VERSION ""

NS_ :

BS_:

BU_:

BO_ 3221225472 VECTOR__INDEPENDENT_SIG_MSG: 0 Vector__XXX
 SG_ TBD : 0|8@1+ (1,0) [0|0] "" Vector__XXX

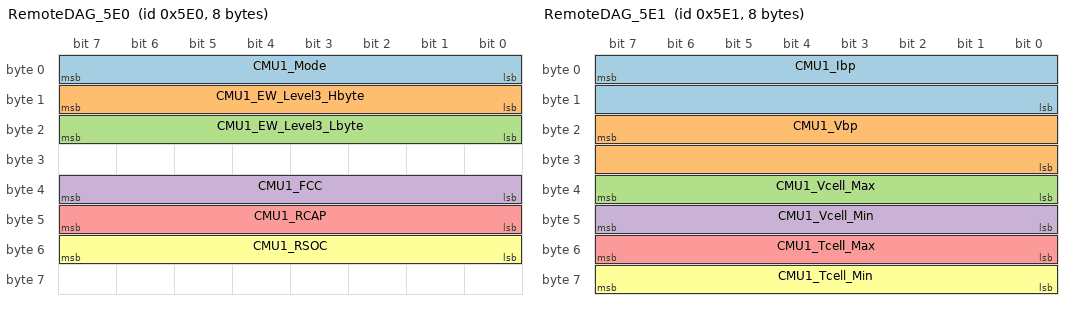
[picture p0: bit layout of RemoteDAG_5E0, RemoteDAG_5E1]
BO_ 1504 RemoteDAG_5E0: 8 Vector__XXX
 SG_ CMU1_Mode : 7|8@0+ (1,0) [0|0] "" Vector__XXX
 SG_ CMU1_EW_Level3_Hbyte : 15|8@0+ (1,0) [0|0] "" Vector__XXX
 SG_ CMU1_EW_Level3_Lbyte : 23|8@0+ (1,0) [0|0] "" Vector__XXX
 SG_ CMU1_FCC : 39|8@0+ (1,0) [0|0] "" Vector__XXX
 SG_ CMU1_RCAP : 47|8@0+ (1,0) [0|0] "" Vector__XXX
 SG_ CMU1_RSOC : 55|8@0+ (1,0) [0|0] "" Vector__XXX

BO_ 1505 RemoteDAG_5E1: 8 Vector__XXX
 SG_ CMU1_Ibp : 7|16@0+ (0.02,-500) [0|0] "" Vector__XXX
 SG_ CMU1_Vbp : 23|16@0+ (0.01,0) [0|0] "" Vector__XXX
 SG_ CMU1_Vcell_Max : 39|8@0+ (1,0) [0|0] "" Vector__XXX
 SG_ CMU1_Vcell_Min : 47|8@0+ (1,0) [0|0] "" Vector__XXX
 SG_ CMU1_Tcell_Max : 55|8@0+ (1,0) [0|0] "" Vector__XXX
 SG_ CMU1_Tcell_Min : 63|8@0+ (1,0) [0|0] "" Vector__XXX

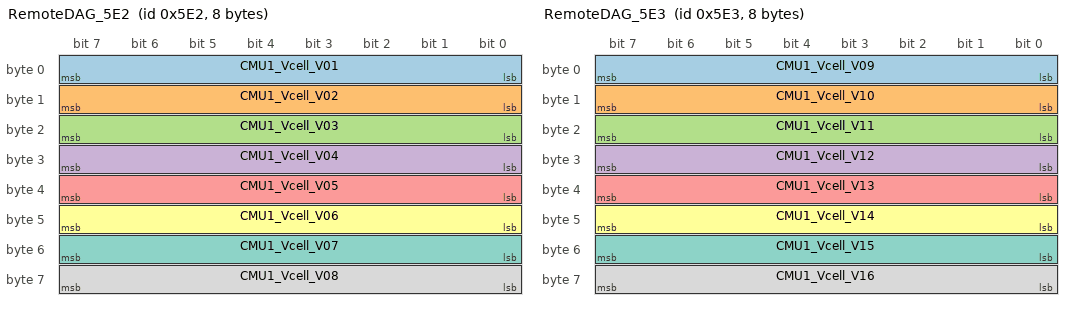
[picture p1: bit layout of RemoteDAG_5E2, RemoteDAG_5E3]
BO_ 1506 RemoteDAG_5E2: 8 Vector__XXX
 SG_ CMU1_Vcell_V01 : 7|8@0+ (1,0) [0|0] "" Vector__XXX
 SG_ CMU1_Vcell_V02 : 15|8@0+ (1,0) [0|0] "" Vector__XXX
 SG_ CMU1_Vcell_V03 : 23|8@0+ (1,0) [0|0] "" Vector__XXX
 SG_ CMU1_Vcell_V04 : 31|8@0+ (1,0) [0|0] "" Vector__XXX
 SG_ CMU1_Vcell_V05 : 39|8@0+ (1,0) [0|0] "" Vector__XXX
 SG_ CMU1_Vcell_V06 : 47|8@0+ (1,0) [0|0] "" Vector__XXX
 SG_ CMU1_Vcell_V07 : 55|8@0+ (1,0) [0|0] "" Vector__XXX
 SG_ CMU1_Vcell_V08 : 63|8@0+ (1,0) [0|0] "" Vector__XXX

BO_ 1507 RemoteDAG_5E3: 8 Vector__XXX
 SG_ CMU1_Vcell_V09 : 7|8@0+ (1,0) [0|0] "" Vector__XXX
 SG_ CMU1_Vcell_V10 : 15|8@0+ (1,0) [0|0] "" Vector__XXX
 SG_ CMU1_Vcell_V11 : 23|8@0+ (1,0) [0|0] "" Vector__XXX
 SG_ CMU1_Vcell_V12 : 31|8@0+ (1,0) [0|0] "" Vector__XXX
 SG_ CMU1_Vcell_V13 : 39|8@0+ (1,0) [0|0] "" Vector__XXX
 SG_ CMU1_Vcell_V14 : 47|8@0+ (1,0) [0|0] "" Vector__XXX
 SG_ CMU1_Vcell_V15 : 55|8@0+ (1,0) [0|0] "" Vector__XXX
 SG_ CMU1_Vcell_V16 : 63|8@0+ (1,0) [0|0] "" Vector__XXX

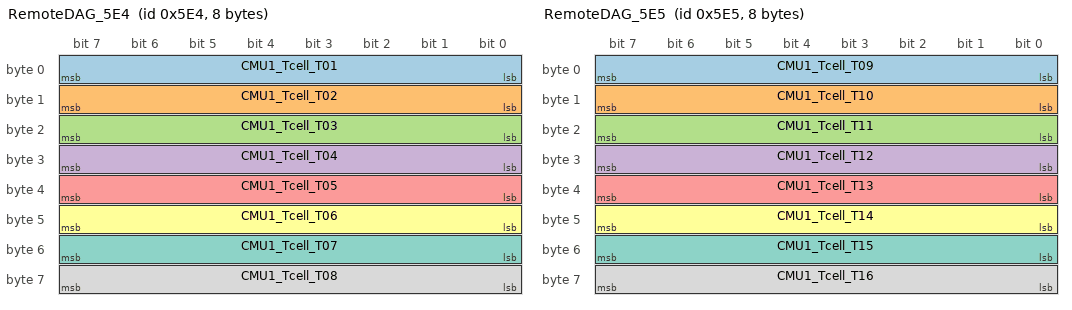
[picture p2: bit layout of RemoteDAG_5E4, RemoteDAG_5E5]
BO_ 1508 RemoteDAG_5E4: 8 Vector__XXX
 SG_ CMU1_Tcell_T01 : 7|8@0+ (1,0) [0|0] "" Vector__XXX
 SG_ CMU1_Tcell_T02 : 15|8@0+ (1,0) [0|0] "" Vector__XXX
 SG_ CMU1_Tcell_T03 : 23|8@0+ (1,0) [0|0] "" Vector__XXX
 SG_ CMU1_Tcell_T04 : 31|8@0+ (1,0) [0|0] "" Vector__XXX
 SG_ CMU1_Tcell_T05 : 39|8@0+ (1,0) [0|0] "" Vector__XXX
 SG_ CMU1_Tcell_T06 : 47|8@0+ (1,0) [0|0] "" Vector__XXX
 SG_ CMU1_Tcell_T07 : 55|8@0+ (1,0) [0|0] "" Vector__XXX
 SG_ CMU1_Tcell_T08 : 63|8@0+ (1,0) [0|0] "" Vector__XXX

BO_ 1509 RemoteDAG_5E5: 8 Vector__XXX
 SG_ CMU1_Tcell_T09 : 7|8@0+ (1,0) [0|0] "" Vector__XXX
 SG_ CMU1_Tcell_T10 : 15|8@0+ (1,0) [0|0] "" Vector__XXX
 SG_ CMU1_Tcell_T11 : 23|8@0+ (1,0) [0|0] "" Vector__XXX
 SG_ CMU1_Tcell_T12 : 31|8@0+ (1,0) [0|0] "" Vector__XXX
 SG_ CMU1_Tcell_T13 : 39|8@0+ (1,0) [0|0] "" Vector__XXX
 SG_ CMU1_Tcell_T14 : 47|8@0+ (1,0) [0|0] "" Vector__XXX
 SG_ CMU1_Tcell_T15 : 55|8@0+ (1,0) [0|0] "" Vector__XXX
 SG_ CMU1_Tcell_T16 : 63|8@0+ (1,0) [0|0] "" Vector__XXX

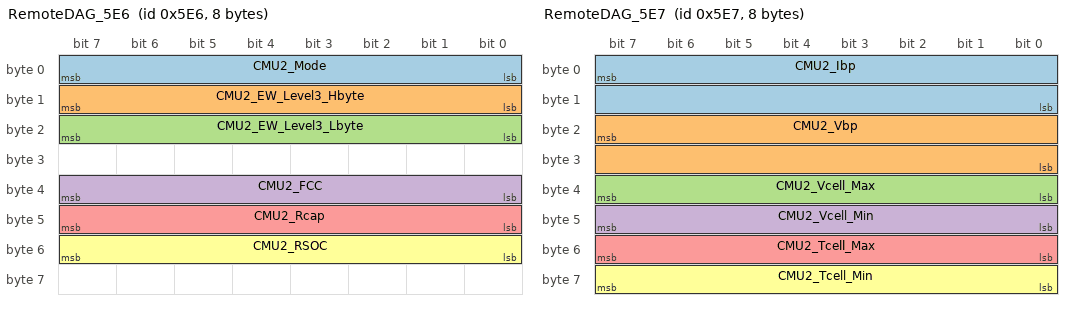
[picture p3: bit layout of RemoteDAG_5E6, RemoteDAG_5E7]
BO_ 1510 RemoteDAG_5E6: 8 Vector__XXX
 SG_ CMU2_Mode : 7|8@0+ (1,0) [0|0] "" Vector__XXX
 SG_ CMU2_EW_Level3_Hbyte : 15|8@0+ (1,0) [0|0] "" Vector__XXX
 SG_ CMU2_EW_Level3_Lbyte : 23|8@0+ (1,0) [0|0] "" Vector__XXX
 SG_ CMU2_FCC : 39|8@0+ (1,0) [0|0] "" Vector__XXX
 SG_ CMU2_Rcap : 47|8@0+ (1,0) [0|0] "" Vector__XXX
 SG_ CMU2_RSOC : 55|8@0+ (1,0) [0|0] "" Vector__XXX

BO_ 1511 RemoteDAG_5E7: 8 Vector__XXX
 SG_ CMU2_Ibp : 7|16@0+ (0.02,-500) [0|0] "" Vector__XXX
 SG_ CMU2_Vbp : 23|16@0+ (0.01,0) [0|0] "" Vector__XXX
 SG_ CMU2_Vcell_Max : 39|8@0+ (1,0) [0|0] "" Vector__XXX
 SG_ CMU2_Vcell_Min : 47|8@0+ (1,0) [0|0] "" Vector__XXX
 SG_ CMU2_Tcell_Max : 55|8@0+ (1,0) [0|0] "" Vector__XXX
 SG_ CMU2_Tcell_Min : 63|8@0+ (1,0) [0|0] "" Vector__XXX

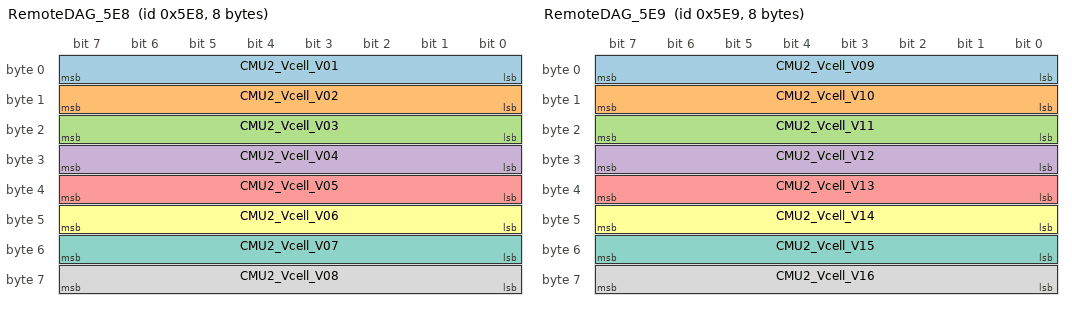
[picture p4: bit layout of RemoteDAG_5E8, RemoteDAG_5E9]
BO_ 1512 RemoteDAG_5E8: 8 Vector__XXX
 SG_ CMU2_Vcell_V01 : 7|8@0+ (1,0) [0|0] "" Vector__XXX
 SG_ CMU2_Vcell_V02 : 15|8@0+ (1,0) [0|0] "" Vector__XXX
 SG_ CMU2_Vcell_V03 : 23|8@0+ (1,0) [0|0] "" Vector__XXX
 SG_ CMU2_Vcell_V04 : 31|8@0+ (1,0) [0|0] "" Vector__XXX
 SG_ CMU2_Vcell_V05 : 39|8@0+ (1,0) [0|0] "" Vector__XXX
 SG_ CMU2_Vcell_V06 : 47|8@0+ (1,0) [0|0] "" Vector__XXX
 SG_ CMU2_Vcell_V07 : 55|8@0+ (1,0) [0|0] "" Vector__XXX
 SG_ CMU2_Vcell_V08 : 63|8@0+ (1,0) [0|0] "" Vector__XXX

BO_ 1513 RemoteDAG_5E9: 8 Vector__XXX
 SG_ CMU2_Vcell_V09 : 7|8@0+ (1,0) [0|0] "" Vector__XXX
 SG_ CMU2_Vcell_V10 : 15|8@0+ (1,0) [0|0] "" Vector__XXX
 SG_ CMU2_Vcell_V11 : 23|8@0+ (1,0) [0|0] "" Vector__XXX
 SG_ CMU2_Vcell_V12 : 31|8@0+ (1,0) [0|0] "" Vector__XXX
 SG_ CMU2_Vcell_V13 : 39|8@0+ (1,0) [0|0] "" Vector__XXX
 SG_ CMU2_Vcell_V14 : 47|8@0+ (1,0) [0|0] "" Vector__XXX
 SG_ CMU2_Vcell_V15 : 55|8@0+ (1,0) [0|0] "" Vector__XXX
 SG_ CMU2_Vcell_V16 : 63|8@0+ (1,0) [0|0] "" Vector__XXX

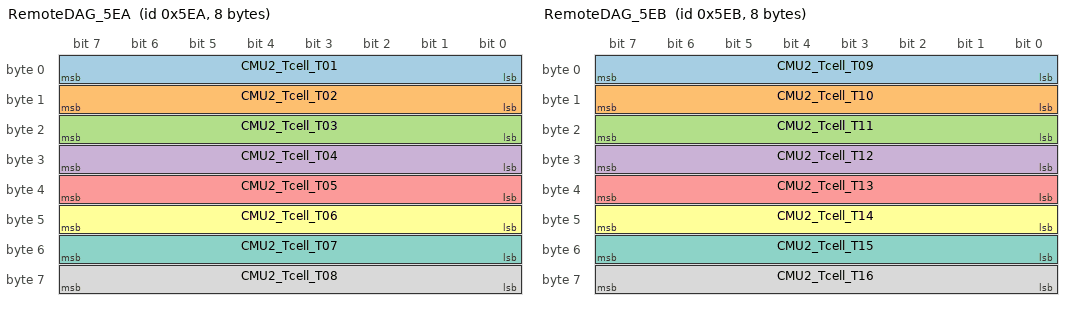
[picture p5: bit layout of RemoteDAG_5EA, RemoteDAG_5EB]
BO_ 1514 RemoteDAG_5EA: 8 Vector__XXX
 SG_ CMU2_Tcell_T01 : 7|8@0+ (1,0) [0|0] "" Vector__XXX
 SG_ CMU2_Tcell_T02 : 15|8@0+ (1,0) [0|0] "" Vector__XXX
 SG_ CMU2_Tcell_T03 : 23|8@0+ (1,0) [0|0] "" Vector__XXX
 SG_ CMU2_Tcell_T04 : 31|8@0+ (1,0) [0|0] "" Vector__XXX
 SG_ CMU2_Tcell_T05 : 39|8@0+ (1,0) [0|0] "" Vector__XXX
 SG_ CMU2_Tcell_T06 : 47|8@0+ (1,0) [0|0] "" Vector__XXX
 SG_ CMU2_Tcell_T07 : 55|8@0+ (1,0) [0|0] "" Vector__XXX
 SG_ CMU2_Tcell_T08 : 63|8@0+ (1,0) [0|0] "" Vector__XXX

BO_ 1515 RemoteDAG_5EB: 8 Vector__XXX
 SG_ CMU2_Tcell_T09 : 7|8@0+ (1,0) [0|0] "" Vector__XXX
 SG_ CMU2_Tcell_T10 : 15|8@0+ (1,0) [0|0] "" Vector__XXX
 SG_ CMU2_Tcell_T11 : 23|8@0+ (1,0) [0|0] "" Vector__XXX
 SG_ CMU2_Tcell_T12 : 31|8@0+ (1,0) [0|0] "" Vector__XXX
 SG_ CMU2_Tcell_T13 : 39|8@0+ (1,0) [0|0] "" Vector__XXX
 SG_ CMU2_Tcell_T14 : 47|8@0+ (1,0) [0|0] "" Vector__XXX
 SG_ CMU2_Tcell_T15 : 55|8@0+ (1,0) [0|0] "" Vector__XXX
 SG_ CMU2_Tcell_T16 : 63|8@0+ (1,0) [0|0] "" Vector__XXX

CM_ BO_ 3221225472 "This is a message for not used signals, created by Vector CANdb++ DBC OLE DB Provider.";
